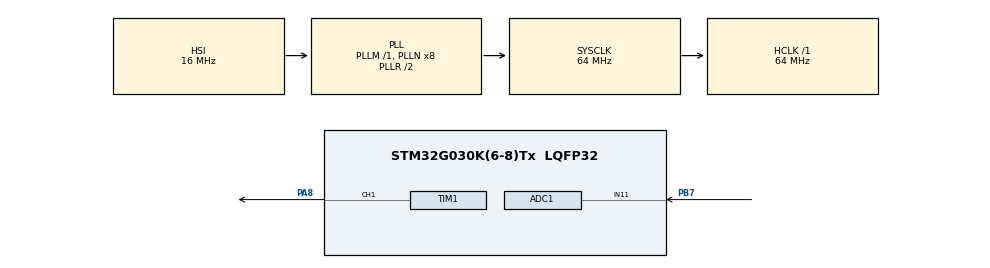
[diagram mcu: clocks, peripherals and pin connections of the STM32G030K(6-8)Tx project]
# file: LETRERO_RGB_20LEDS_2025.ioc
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ADC1.Channel-0\#ChannelRegularConversion=ADC_CHANNEL_11
ADC1.NbrOfConversionFlag=1
ADC1.Rank-0\#ChannelRegularConversion=1
ADC1.SamplingTime-0\#ChannelRegularConversion=ADC_SAMPLINGTIME_COMMON_1
ADC1.SamplingTimeCommon1=ADC_SAMPLETIME_160CYCLES_5
ADC1.SamplingTimeCommon2=ADC_SAMPLETIME_160CYCLES_5
ADC1.SelectedChannel=ADC_CHANNEL_11
ADC1.master=1
Dma.Request0=TIM1_CH1
Dma.TIM1_CH1.0.Direction=DMA_MEMORY_TO_PERIPH
Dma.TIM1_CH1.0.EventEnable=DISABLE
Dma.TIM1_CH1.0.Instance=DMA1_Channel1
Dma.TIM1_CH1.0.MemDataAlignment=DMA_MDATAALIGN_HALFWORD
Dma.TIM1_CH1.0.MemInc=DMA_MINC_ENABLE
Dma.TIM1_CH1.0.Mode=DMA_NORMAL
Dma.TIM1_CH1.0.PeriphDataAlignment=DMA_PDATAALIGN_HALFWORD
Dma.TIM1_CH1.0.PeriphInc=DMA_PINC_DISABLE
Dma.TIM1_CH1.0.Polarity=HAL_DMAMUX_REQ_GEN_RISING
Dma.TIM1_CH1.0.Priority=DMA_PRIORITY_LOW
Dma.TIM1_CH1.0.RequestNumber=1
Dma.TIM1_CH1.0.SignalID=NONE
Dma.TIM1_CH1.0.SyncEnable=DISABLE
Dma.TIM1_CH1.0.SyncPolarity=HAL_DMAMUX_SYNC_NO_EVENT
Dma.TIM1_CH1.0.SyncRequestNumber=1
Dma.TIM1_CH1.0.SyncSignalID=NONE
Mcu.Family=STM32G0
Mcu.Name=STM32G030K(6-8)Tx
Mcu.Package=LQFP32
NVIC.ADC1_IRQn=true\:0\:0\:false\:false\:true\:true\:true\:true
NVIC.DMA1_Channel1_IRQn=true\:0\:0\:false\:false\:true\:false\:true\:true
PA13.Mode=Serial_Wire
PA13.Signal=SYS_SWDIO
PA14-BOOT0.Mode=Serial_Wire
PA14-BOOT0.Signal=SYS_SWCLK
PA8.Signal=S_TIM1_CH1
PB7.Mode=IN11
PB7.Signal=ADC1_IN11
ProjectManager.HeapSize=0x200
ProjectManager.StackSize=0x400
ProjectManager.TargetToolchain=STM32CubeIDE
RCC.ADCFreq_Value=64000000
RCC.AHBFreq_Value=64000000
RCC.CortexFreq_Value=64000000
RCC.EXTERNAL_CLOCK_VALUE=12288000
RCC.HCLKFreq_Value=64000000
RCC.HSE_VALUE=8000000
RCC.HSI_VALUE=16000000
RCC.LSE_VALUE=32768
RCC.SYSCLKFreq_VALUE=64000000
RCC.SYSCLKSource=RCC_SYSCLKSOURCE_PLLCLK
RCC.VCOOutputFreq_Value=128000000
SH.S_TIM1_CH1.0=TIM1_CH1,PWM Generation1 CH1
TIM1.Channel-PWM\ Generation1\ CH1=TIM_CHANNEL_1
TIM1.Period=80-1
board=custom

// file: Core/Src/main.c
/* USER CODE BEGIN Header */
/**
  ******************************************************************************
  * @file           : main.c
  * @brief          : Main program body
  ******************************************************************************
  * @attention
  *
  * Copyright (c) 2025 STMicroelectronics.
  * All rights reserved.
  *
  * This software is licensed under terms that can be found in the LICENSE file
  * in the root directory of this software component.
  * If no LICENSE file comes with this software, it is provided AS-IS.
  *
  ******************************************************************************
  */
/* USER CODE END Header */
#include "main.h"

/* USER CODE BEGIN Includes */
#include "Anglas_WS281X.h"
/* USER CODE END Includes */

ADC_HandleTypeDef hadc1;

TIM_HandleTypeDef htim1;
DMA_HandleTypeDef hdma_tim1_ch1;

void SystemClock_Config(void);
static void MX_GPIO_Init(void);
static void MX_DMA_Init(void);
static void MX_ADC1_Init(void);
static void MX_TIM1_Init(void);
/* USER CODE BEGIN PFP */
float Refresh_ADC_Value(void);
/* USER CODE END PFP */

int main(void)
{

  /* MCU Configuration--------------------------------------------------------*/

  /* Reset of all peripherals, Initializes the Flash interface and the Systick. */
  HAL_Init();

  /* Configure the system clock */
  SystemClock_Config();

  /* Initialize all configured peripherals */
  MX_GPIO_Init();
  MX_DMA_Init();
  MX_ADC1_Init();
  MX_TIM1_Init();
  /* USER CODE BEGIN 2 */
  HAL_ADC_Start_IT(&hadc1);
  HAL_Delay(1500);
  WS2811_Init();

  /* USER CODE END 2 */

  /* Infinite loop */
  /* USER CODE BEGIN WHILE */
  while (1)
  {
	  ArmarIzquierda1Color(2000);
	  ArmarIzquierdaColores(1,2000);
	  RuedaColor(1,20);//okkkk
	  Arcoiris_Der(50, 80);//okkkk, genial aqui el Arcoiris_Der resalta el rojo y luego BarridoColoresDerIzq empienza con rojo
	  BarridoColoresDerIzq(50,500);//okkkk, genial BarridoColoresDerIzq termina en blanco y GradienteColores empieza en blanco
	  GradienteColores(50,70);//okkkk

	  Respirar(1,1,AZUL);//okKKK
	  Respirar(1,1,ROJO);//okKKK
	  VolumenAbrirColores(1,200);//okkkk
	  RuedaColor(8,1);
	  VolumenCerrarColores(1,100);
	  RuedaColor(8,1);

	  Respirar(1,1,AMARILLO);//okKKK
	  Respirar(1,1,CIAN);//okKKK
	  BarridoColoresDer(80,500);//okkkk

	  ArmarIzquierdaColores(1,2000);

	  Respirar(1,1,VERDE);//okKKK
	  Respirar(1,1,BLANCO);//okKKK
	  GirarColores(60,1000);//okkkk

	  ArmarIzquierdaColores(1,2000);

	  Respirar(1,1,ROJO);//okKKK
	  Respirar(1,1,MAGENTA);//okKKK
	  RuedaColor(15,1);

    /* USER CODE END WHILE */

  }
}

void SystemClock_Config(void)
{
  RCC_OscInitTypeDef RCC_OscInitStruct = {0};
  RCC_ClkInitTypeDef RCC_ClkInitStruct = {0};

  /** Configure the main internal regulator output voltage
  */
  HAL_PWREx_ControlVoltageScaling(PWR_REGULATOR_VOLTAGE_SCALE1);

  /** Initializes the RCC Oscillators according to the specified parameters
  * in the RCC_OscInitTypeDef structure.
  */
  RCC_OscInitStruct.OscillatorType = RCC_OSCILLATORTYPE_HSI;
  RCC_OscInitStruct.HSIState = RCC_HSI_ON;
  RCC_OscInitStruct.HSIDiv = RCC_HSI_DIV1;
  RCC_OscInitStruct.HSICalibrationValue = RCC_HSICALIBRATION_DEFAULT;
  RCC_OscInitStruct.PLL.PLLState = RCC_PLL_ON;
  RCC_OscInitStruct.PLL.PLLSource = RCC_PLLSOURCE_HSI;
  RCC_OscInitStruct.PLL.PLLM = RCC_PLLM_DIV1;
  RCC_OscInitStruct.PLL.PLLN = 8;
  RCC_OscInitStruct.PLL.PLLP = RCC_PLLP_DIV2;
  RCC_OscInitStruct.PLL.PLLR = RCC_PLLR_DIV2;
  if (HAL_RCC_OscConfig(&RCC_OscInitStruct) != HAL_OK)
  {
    Error_Handler();
  }

  /** Initializes the CPU, AHB and APB buses clocks
  */
  RCC_ClkInitStruct.ClockType = RCC_CLOCKTYPE_HCLK|RCC_CLOCKTYPE_SYSCLK
                              |RCC_CLOCKTYPE_PCLK1;
  RCC_ClkInitStruct.SYSCLKSource = RCC_SYSCLKSOURCE_PLLCLK;
  RCC_ClkInitStruct.AHBCLKDivider = RCC_SYSCLK_DIV1;
  RCC_ClkInitStruct.APB1CLKDivider = RCC_HCLK_DIV1;

  if (HAL_RCC_ClockConfig(&RCC_ClkInitStruct, FLASH_LATENCY_2) != HAL_OK)
  {
    Error_Handler();
  }
}

static void MX_ADC1_Init(void)
{

  ADC_ChannelConfTypeDef sConfig = {0};

  /** Configure the global features of the ADC (Clock, Resolution, Data Alignment and number of conversion)
  */
  hadc1.Instance = ADC1;
  hadc1.Init.ClockPrescaler = ADC_CLOCK_SYNC_PCLK_DIV2;
  hadc1.Init.Resolution = ADC_RESOLUTION_12B;
  hadc1.Init.DataAlign = ADC_DATAALIGN_RIGHT;
  hadc1.Init.ScanConvMode = ADC_SCAN_DISABLE;
  hadc1.Init.EOCSelection = ADC_EOC_SINGLE_CONV;
  hadc1.Init.LowPowerAutoWait = DISABLE;
  hadc1.Init.LowPowerAutoPowerOff = DISABLE;
  hadc1.Init.ContinuousConvMode = DISABLE;
  hadc1.Init.NbrOfConversion = 1;
  hadc1.Init.DiscontinuousConvMode = DISABLE;
  hadc1.Init.ExternalTrigConv = ADC_SOFTWARE_START;
  hadc1.Init.ExternalTrigConvEdge = ADC_EXTERNALTRIGCONVEDGE_NONE;
  hadc1.Init.DMAContinuousRequests = DISABLE;
  hadc1.Init.Overrun = ADC_OVR_DATA_PRESERVED;
  hadc1.Init.SamplingTimeCommon1 = ADC_SAMPLETIME_160CYCLES_5;
  hadc1.Init.SamplingTimeCommon2 = ADC_SAMPLETIME_160CYCLES_5;
  hadc1.Init.OversamplingMode = DISABLE;
  hadc1.Init.TriggerFrequencyMode = ADC_TRIGGER_FREQ_HIGH;
  if (HAL_ADC_Init(&hadc1) != HAL_OK)
  {
    Error_Handler();
  }

  /** Configure Regular Channel
  */
  sConfig.Channel = ADC_CHANNEL_11;
  sConfig.Rank = ADC_REGULAR_RANK_1;
  sConfig.SamplingTime = ADC_SAMPLINGTIME_COMMON_1;
  if (HAL_ADC_ConfigChannel(&hadc1, &sConfig) != HAL_OK)
  {
    Error_Handler();
  }

}

static void MX_TIM1_Init(void)
{

  TIM_MasterConfigTypeDef sMasterConfig = {0};
  TIM_OC_InitTypeDef sConfigOC = {0};
  TIM_BreakDeadTimeConfigTypeDef sBreakDeadTimeConfig = {0};

  htim1.Instance = TIM1;
  htim1.Init.Prescaler = 0;
  htim1.Init.CounterMode = TIM_COUNTERMODE_UP;
  htim1.Init.Period = 80-1;
  htim1.Init.ClockDivision = TIM_CLOCKDIVISION_DIV1;
  htim1.Init.RepetitionCounter = 0;
  htim1.Init.AutoReloadPreload = TIM_AUTORELOAD_PRELOAD_DISABLE;
  if (HAL_TIM_PWM_Init(&htim1) != HAL_OK)
  {
    Error_Handler();
  }
  sMasterConfig.MasterOutputTrigger = TIM_TRGO_RESET;
  sMasterConfig.MasterOutputTrigger2 = TIM_TRGO2_RESET;
  sMasterConfig.MasterSlaveMode = TIM_MASTERSLAVEMODE_DISABLE;
  if (HAL_TIMEx_MasterConfigSynchronization(&htim1, &sMasterConfig) != HAL_OK)
  {
    Error_Handler();
  }
  sConfigOC.OCMode = TIM_OCMODE_PWM1;
  sConfigOC.Pulse = 0;
  sConfigOC.OCPolarity = TIM_OCPOLARITY_HIGH;
  sConfigOC.OCNPolarity = TIM_OCNPOLARITY_HIGH;
  sConfigOC.OCFastMode = TIM_OCFAST_DISABLE;
  sConfigOC.OCIdleState = TIM_OCIDLESTATE_RESET;
  sConfigOC.OCNIdleState = TIM_OCNIDLESTATE_RESET;
  if (HAL_TIM_PWM_ConfigChannel(&htim1, &sConfigOC, TIM_CHANNEL_1) != HAL_OK)
  {
    Error_Handler();
  }
  sBreakDeadTimeConfig.OffStateRunMode = TIM_OSSR_DISABLE;
  sBreakDeadTimeConfig.OffStateIDLEMode = TIM_OSSI_DISABLE;
  sBreakDeadTimeConfig.LockLevel = TIM_LOCKLEVEL_OFF;
  sBreakDeadTimeConfig.DeadTime = 0;
  sBreakDeadTimeConfig.BreakState = TIM_BREAK_DISABLE;
  sBreakDeadTimeConfig.BreakPolarity = TIM_BREAKPOLARITY_HIGH;
  sBreakDeadTimeConfig.BreakFilter = 0;
  sBreakDeadTimeConfig.BreakAFMode = TIM_BREAK_AFMODE_INPUT;
  sBreakDeadTimeConfig.Break2State = TIM_BREAK2_DISABLE;
  sBreakDeadTimeConfig.Break2Polarity = TIM_BREAK2POLARITY_HIGH;
  sBreakDeadTimeConfig.Break2Filter = 0;
  sBreakDeadTimeConfig.Break2AFMode = TIM_BREAK_AFMODE_INPUT;
  sBreakDeadTimeConfig.AutomaticOutput = TIM_AUTOMATICOUTPUT_DISABLE;
  if (HAL_TIMEx_ConfigBreakDeadTime(&htim1, &sBreakDeadTimeConfig) != HAL_OK)
  {
    Error_Handler();
  }
  HAL_TIM_MspPostInit(&htim1);

}

static void MX_DMA_Init(void)
{

  /* DMA controller clock enable */
  __HAL_RCC_DMA1_CLK_ENABLE();

  /* DMA interrupt init */
  /* DMA1_Channel1_IRQn interrupt configuration */
  HAL_NVIC_SetPriority(DMA1_Channel1_IRQn, 0, 0);
  HAL_NVIC_EnableIRQ(DMA1_Channel1_IRQn);

}

static void MX_GPIO_Init(void)
{

  /* GPIO Ports Clock Enable */
  __HAL_RCC_GPIOA_CLK_ENABLE();
  __HAL_RCC_GPIOB_CLK_ENABLE();

}

/* USER CODE BEGIN 4 */
float Refresh_ADC_Value(void){
	static uint16_t adc;
	static float vel;
	adc = HAL_ADC_GetValue(&hadc1);
	vel = (float)adc/1023;
	HAL_ADC_Start_IT(&hadc1);
	return vel;
}
/* USER CODE END 4 */

void Error_Handler(void)
{
  __disable_irq();
  while (1)
  {
  }
}
